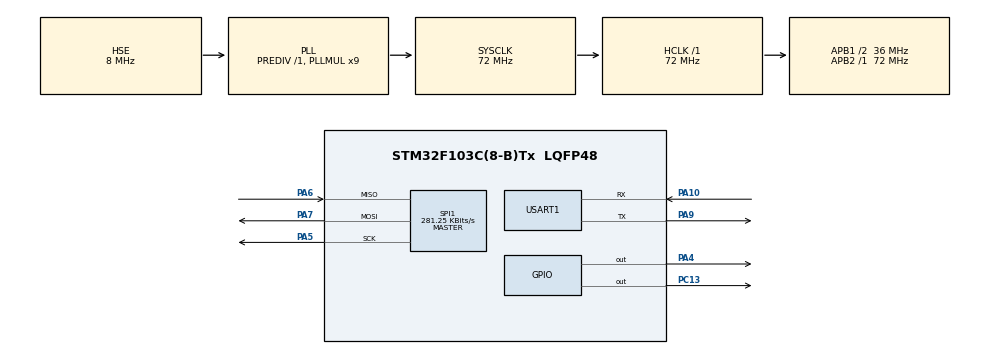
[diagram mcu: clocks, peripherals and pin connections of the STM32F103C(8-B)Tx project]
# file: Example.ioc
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FREERTOS.Tasks01=logger,0,512,StartLogger,Default,NULL,Dynamic,NULL,NULL
FREERTOS.configMAX_PRIORITIES=5
FREERTOS.configTOTAL_HEAP_SIZE=8192
Mcu.Family=STM32F1
Mcu.Name=STM32F103C(8-B)Tx
Mcu.Package=LQFP48
NVIC.PriorityGroup=NVIC_PRIORITYGROUP_4
NVIC.TIM2_IRQn=true\:15\:0\:false\:false\:true\:false\:false\:true\:true
NVIC.TimeBase=TIM2_IRQn
NVIC.TimeBaseIP=TIM2
PA10.Mode=Asynchronous
PA10.Signal=USART1_RX
PA4.Signal=GPIO_Output
PA5.Mode=Full_Duplex_Master
PA5.Signal=SPI1_SCK
PA6.Mode=Full_Duplex_Master
PA6.Signal=SPI1_MISO
PA7.Mode=Full_Duplex_Master
PA7.Signal=SPI1_MOSI
PA9.Mode=Asynchronous
PA9.Signal=USART1_TX
PC13-TAMPER-RTC.Signal=GPIO_Output
PD0-OSC_IN.Mode=HSE-External-Oscillator
PD0-OSC_IN.Signal=RCC_OSC_IN
PD1-OSC_OUT.Mode=HSE-External-Oscillator
PD1-OSC_OUT.Signal=RCC_OSC_OUT
ProjectManager.HeapSize=0x200
ProjectManager.StackSize=0x400
ProjectManager.TargetToolchain=Makefile
RCC.AHBFreq_Value=72000000
RCC.APB1CLKDivider=RCC_HCLK_DIV2
RCC.APB1Freq_Value=36000000
RCC.APB1TimFreq_Value=72000000
RCC.APB2Freq_Value=72000000
RCC.APB2TimFreq_Value=72000000
RCC.HCLKFreq_Value=72000000
RCC.PLLMUL=RCC_PLL_MUL9
RCC.PLLSourceVirtual=RCC_PLLSOURCE_HSE
RCC.SYSCLKFreq_VALUE=72000000
RCC.SYSCLKSource=RCC_SYSCLKSOURCE_PLLCLK
RCC.USBFreq_Value=72000000
SPI1.BaudRatePrescaler=SPI_BAUDRATEPRESCALER_256
SPI1.CalculateBaudRate=281.25 KBits/s
SPI1.Direction=SPI_DIRECTION_2LINES
SPI1.Mode=SPI_MODE_MASTER
SPI1.VirtualType=VM_MASTER
USART1.VirtualMode=VM_ASYNC
VP_FATFS_VS_Generic.Mode=User_defined
VP_FREERTOS_VS_CMSIS_V1.Mode=CMSIS_V1
VP_SYS_VS_ND.Mode=No_Debug
VP_SYS_VS_tim2.Mode=TIM2
board=custom

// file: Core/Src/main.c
/* USER CODE BEGIN Header */
/**
  ******************************************************************************
  * @file           : main.c
  * @brief          : Main program body
  ******************************************************************************
  * @attention
  *
  * Copyright (c) 2026 STMicroelectronics.
  * All rights reserved.
  *
  * This software is licensed under terms that can be found in the LICENSE file
  * in the root directory of this software component.
  * If no LICENSE file comes with this software, it is provided AS-IS.
  *
  ******************************************************************************
  */
/* USER CODE END Header */
#include "main.h"
#include "cmsis_os.h"
#include "fatfs.h"
#include "fatfs_sd.h"
#include "spi.h"
#include "usart.h"
#include "gpio.h"
#include <stdio.h>

/* Variables para los Timeouts de la SD */
volatile uint8_t Timer1, Timer2;

void SystemClock_Config(void);
void MX_FREERTOS_Init(void);

int main(void)
{

  /* MCU Configuration--------------------------------------------------------*/

  /* Reset of all peripherals, Initializes the Flash interface and the Systick. */
  HAL_Init();

  /* Configure the system clock */
  SystemClock_Config();

  /* Initialize all configured peripherals */
  MX_GPIO_Init();
  MX_USART1_UART_Init();
  printf("Inicializacion UART\r\n");
  MX_SPI1_Init();
  printf("Inicializacion SPI\r\n");
  MX_FATFS_Init();
  printf("Inicializacion FATFS\r\n");

  /* Call init function for freertos objects (in cmsis_os2.c) */
  MX_FREERTOS_Init();

  /* Start scheduler */
  osKernelStart();

  /* We should never get here as control is now taken by the scheduler */

  /* Infinite loop */
  while (1)
  {

  }
}

void SystemClock_Config(void)
{
  RCC_OscInitTypeDef RCC_OscInitStruct = {0};
  RCC_ClkInitTypeDef RCC_ClkInitStruct = {0};

  /** Initializes the RCC Oscillators according to the specified parameters
  * in the RCC_OscInitTypeDef structure.
  */
  RCC_OscInitStruct.OscillatorType = RCC_OSCILLATORTYPE_HSE;
  RCC_OscInitStruct.HSEState = RCC_HSE_ON;
  RCC_OscInitStruct.HSEPredivValue = RCC_HSE_PREDIV_DIV1;
  RCC_OscInitStruct.HSIState = RCC_HSI_ON;
  RCC_OscInitStruct.PLL.PLLState = RCC_PLL_ON;
  RCC_OscInitStruct.PLL.PLLSource = RCC_PLLSOURCE_HSE;
  RCC_OscInitStruct.PLL.PLLMUL = RCC_PLL_MUL9;
  if (HAL_RCC_OscConfig(&RCC_OscInitStruct) != HAL_OK)
  {
    Error_Handler();
  }

  /** Initializes the CPU, AHB and APB buses clocks
  */
  RCC_ClkInitStruct.ClockType = RCC_CLOCKTYPE_HCLK|RCC_CLOCKTYPE_SYSCLK
                              |RCC_CLOCKTYPE_PCLK1|RCC_CLOCKTYPE_PCLK2;
  RCC_ClkInitStruct.SYSCLKSource = RCC_SYSCLKSOURCE_PLLCLK;
  RCC_ClkInitStruct.AHBCLKDivider = RCC_SYSCLK_DIV1;
  RCC_ClkInitStruct.APB1CLKDivider = RCC_HCLK_DIV2;
  RCC_ClkInitStruct.APB2CLKDivider = RCC_HCLK_DIV1;

  if (HAL_RCC_ClockConfig(&RCC_ClkInitStruct, FLASH_LATENCY_2) != HAL_OK)
  {
    Error_Handler();
  }
}

void HAL_TIM_PeriodElapsedCallback(TIM_HandleTypeDef *htim)
{
  if (htim->Instance == TIM2)
  {
    HAL_IncTick();
  }
  /* USER CODE BEGIN Callback 1 */
  /*--- CONTADORES PARA EL DRIVER SD ---*/
    if (Timer1 > 0) Timer1--;
    if (Timer2 > 0) Timer2--;
  /* USER CODE END Callback 1 */
}
int _write(int file, char *ptr, int len)
{
    HAL_UART_Transmit(&huart1, (uint8_t*)ptr, len, HAL_MAX_DELAY);
    return len;
}

void Error_Handler(void)
{
  __disable_irq();
  while (1)
  {
  }
}

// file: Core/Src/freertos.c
/* USER CODE BEGIN Header */
/**
  ******************************************************************************
  * File Name          : freertos.c
  * Description        : Code for freertos applications
  ******************************************************************************
  * @attention
  *
  * Copyright (c) 2026 STMicroelectronics.
  * All rights reserved.
  *
  * This software is licensed under terms that can be found in the LICENSE file
  * in the root directory of this software component.
  * If no LICENSE file comes with this software, it is provided AS-IS.
  *
  ******************************************************************************
  */
/* USER CODE END Header */

#include "FreeRTOS.h"
#include "task.h"
#include "main.h"
#include "cmsis_os.h"

/* USER CODE BEGIN Includes */
#include "ff.h"
#include "ff_gen_drv.h"
#include "fatfs.h"
#include "fatfs_sd.h"
#include <string.h>
#include <stdio.h>
/* USER CODE END Includes */

osThreadId loggerHandle;

void StartLogger(void const * argument);

void MX_FREERTOS_Init(void); /* (MISRA C 2004 rule 8.1) */

/* GetIdleTaskMemory prototype (linked to static allocation support) */
void vApplicationGetIdleTaskMemory( StaticTask_t **ppxIdleTaskTCBBuffer, StackType_t **ppxIdleTaskStackBuffer, uint32_t *pulIdleTaskStackSize );

/* USER CODE BEGIN GET_IDLE_TASK_MEMORY */
static StaticTask_t xIdleTaskTCBBuffer;
static StackType_t xIdleStack[configMINIMAL_STACK_SIZE];

void vApplicationGetIdleTaskMemory( StaticTask_t **ppxIdleTaskTCBBuffer, StackType_t **ppxIdleTaskStackBuffer, uint32_t *pulIdleTaskStackSize )
{
  *ppxIdleTaskTCBBuffer = &xIdleTaskTCBBuffer;
  *ppxIdleTaskStackBuffer = &xIdleStack[0];
  *pulIdleTaskStackSize = configMINIMAL_STACK_SIZE;
  /* place for user code */
}
/* USER CODE END GET_IDLE_TASK_MEMORY */

void MX_FREERTOS_Init(void) {

  /* Create the thread(s) */
  /* definition and creation of logger */
  osThreadDef(logger, StartLogger, osPriorityNormal, 0, 512);
  loggerHandle = osThreadCreate(osThread(logger), NULL);

}

void StartLogger(void const * argument)
{
  FATFS fs;         // Objeto del sistema de archivos
  FIL file;          // Objeto del archivo
  FRESULT res;       // Resultado de las operaciones FatFS
  UINT bw;           // Bytes escritos
  char buffer[64];   // Buffer para mensajes
  int contador = 0;

  printf("\r\n--- Iniciando Tarea SD ---\r\n");

  /* 1. Montar la SD */
  // El '1' al final fuerza el montaje inmediato (llama a SD_disk_initialize)
  res = f_mount(&fs, USERPath, 1);

  if (res != FR_OK) {
      printf("Error al montar SD: %d\r\n", res);
      // Si falla, podrías intentar un reintento tras un delay
      osDelay(1000);
      res = f_mount(&fs, USERPath, 1);
  }

  if (res == FR_OK) {
      printf("¡SD montada con éxito!\r\n");

      /* 2. Abrir o Crear el archivo */
      // FA_OPEN_ALWAYS: Abre si existe, crea si no.
      // FA_WRITE: Acceso de escritura.
      res = f_open(&file, "LOG.TXT", FA_OPEN_ALWAYS | FA_WRITE);

      if (res == FR_OK) {
          /* 3. Ir al final del archivo para hacer un 'Append' */
          f_lseek(&file, f_size(&file));

          f_printf(&file, "--- Nueva Sesion de Log ---\n");

          /* Bucle infinito de escritura */
          for(;;) {
              contador++;
              sprintf(buffer, "Log numero: %d | Status: OK\r\n", contador);

              res = f_write(&file, buffer, strlen(buffer), &bw);

              if (res == FR_OK) {
                  // f_sync asegura que los datos se guarden físicamente
                  // sin tener que cerrar el archivo constantemente.
                  f_sync(&file);

                  // Opcional: Toggle LED para feedback visual de escritura
                  HAL_GPIO_TogglePin(GPIOC, GPIO_PIN_13);
              } else {
                  printf("Error escribiendo: %d\r\n", res);
                  break; // Salir si hay error físico (ej. sacaron la SD)
              }

              osDelay(1000); // Esperar 1 segundo
          }

          f_close(&file); // Cerrar si sale del bucle
      } else {
          printf("No se pudo abrir el archivo: %d\r\n", res);
      }
  }

  /* Si llegamos aquí es por un error crítico */
  for(;;) {
      osDelay(1000);
  }
}
